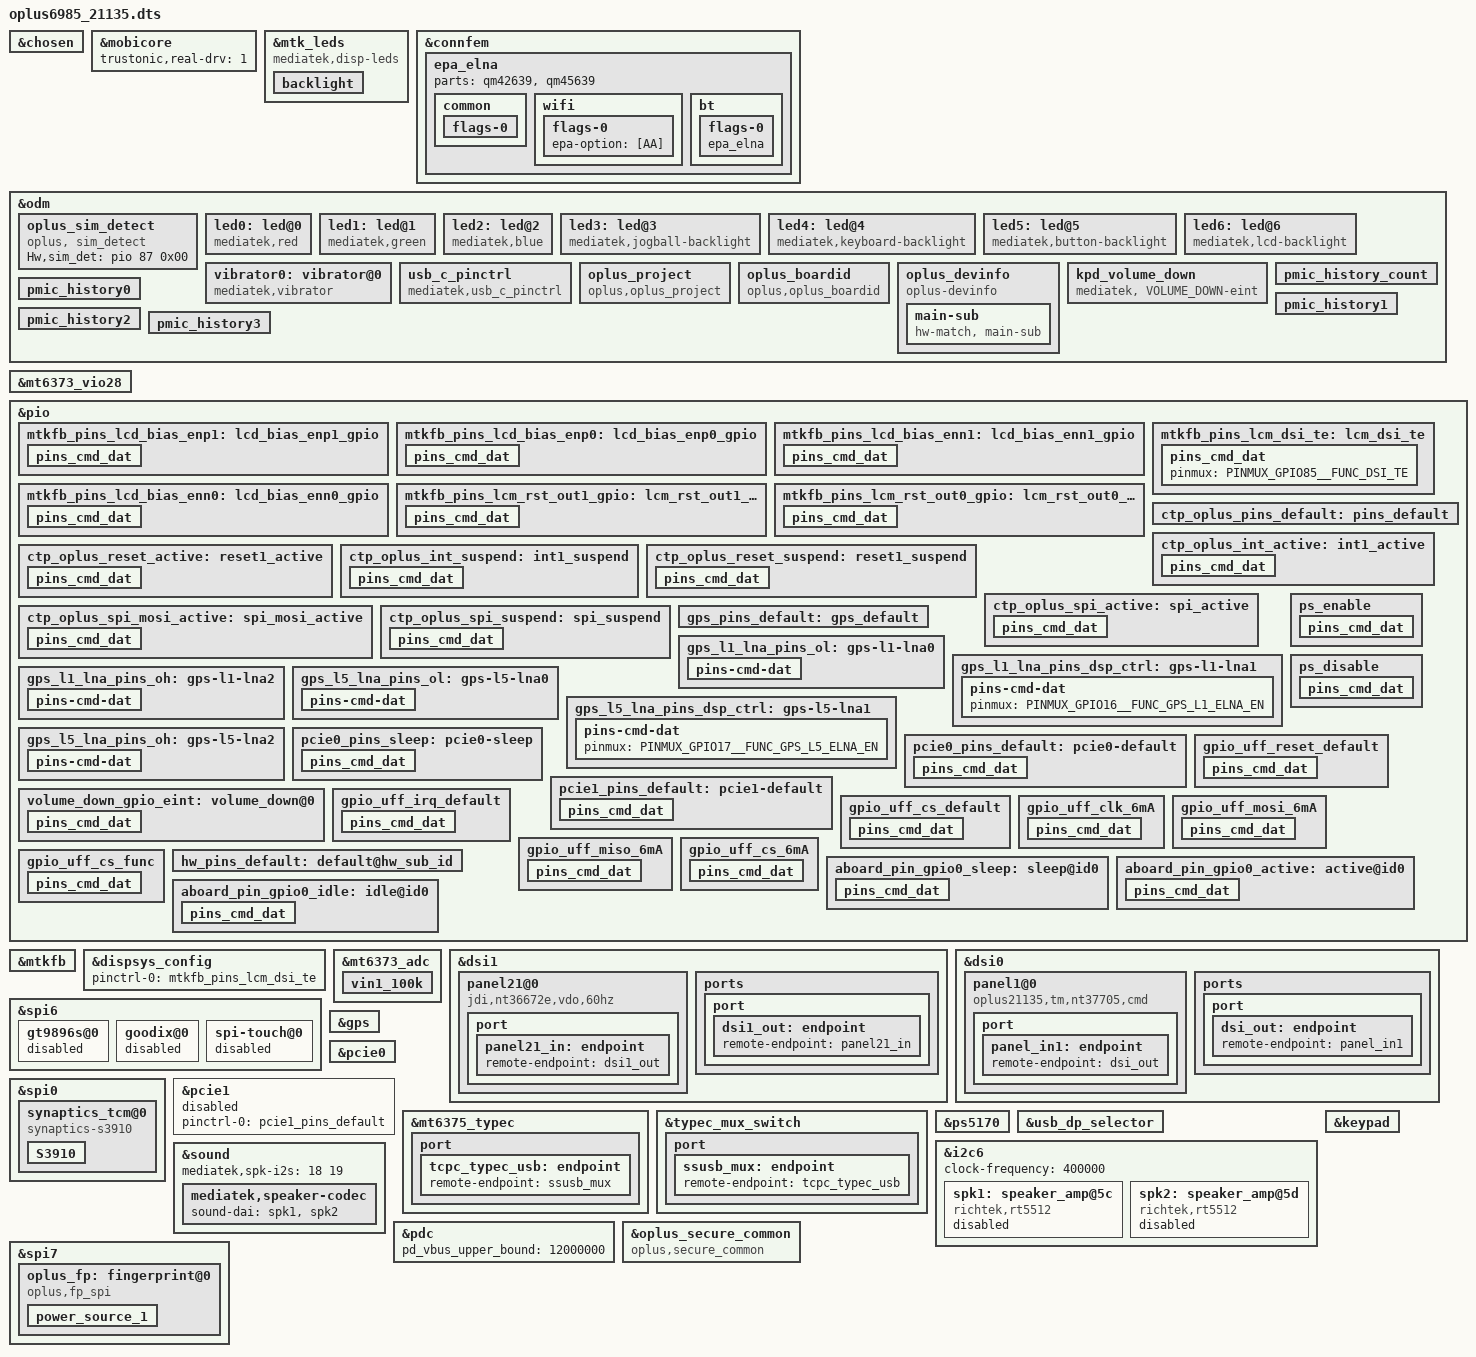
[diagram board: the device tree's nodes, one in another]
// SPDX-License-Identifier: (GPL-2.0 OR MIT)
/*
 * Copyright (C) 2022 MediaTek Inc.
 */
/dts-v1/;
/plugin/;
#include <dt-bindings/interrupt-controller/arm-gic.h>
#include <dt-bindings/interrupt-controller/irq.h>
#include <dt-bindings/pinctrl/mt6985-pinfunc.h>
#include <dt-bindings/phy/phy.h>

/* #ifdef OPLUS_FEATURE_CHG_BASIC */
/* Add for DX-2 charge device-tree */
#include "mediatek/oplus_charge_21135.dtsi"
/* #endif */

//#ifdef OPLUS_FEATURE_SENSOR
#include "mediatek/oplus_sensor_21135.dtsi"
//#endif

&chosen {
bootargs_ext = "console=tty0 root=/dev/ram vmalloc=400M \
loglevel=8 \
androidboot.hardware=mt6985 \
8250.nr_uarts=4 \
initcall_debug=1 \
mtk_printk_ctrl.disable_uart=0";
};

/* Trustonic Mobicore real driver */
&mobicore {
        trustonic,real-drv = <1>;
};

&mtk_leds {
	compatible = "mediatek,i2c-leds";

	backlight {
		led_mode = <6>;
		gate_enable = <1>;
		pwm_config = <0 1 0 0 0>;
	};
};

&connfem {
	/* Support Wifi & BT ePA/eLNA FEM on customer load */
	epa_elna {
		parts = <&qm42639 &qm45639>;

		common {
			flags-0 {
				rx-mode = [35];
				fe-ant-cnt = [82];
				fe-main-bt-share-lp2g = [80];
				fe-conn-spdt = [88];
				fe-reserved = [81];
			};
		};

		wifi {
			flags-0 {
				/* open-loop; */
				epa-option = [AA];
			};
		};

		bt {
			flags-0 {
				/* choose one of: epa_elna/epa/elna/bypass */
				epa_elna;
			};
		};
	};
};

&odm {
/* Add for sim detect */
    oplus_sim_detect {
        compatible = "oplus, sim_detect";
        Hw,sim_det = <&pio 87 0x00>;
    };
};

&mt6373_vio28 {
	regulator-compatible = "VIO28";
	regulator-name = "mt6373_vio28";
	status = "okay";
	regulator-min-microvolt = <3000000>;
	regulator-max-microvolt = <3000000>;
	regulator-always-on;
};

/** #ifdef OPLUS_DISPLAY_FEATURE **/
&odm {
	led0:led@0 {
		compatible = "mediatek,red";
		led_mode = <0>;
		data = <1>;
		pwm_config = <0 0 0 0 0>;
	};
	led1:led@1 {
		compatible = "mediatek,green";
		led_mode = <0>;
		data = <1>;
		pwm_config = <0 0 0 0 0>;
	};
	led2:led@2 {
		compatible = "mediatek,blue";
		led_mode = <0>;
		data = <1>;
		pwm_config = <0 0 0 0 0>;
	};
	led3:led@3 {
		compatible = "mediatek,jogball-backlight";
		led_mode = <0>;
		data = <1>;
		pwm_config = <0 0 0 0 0>;
	};
	led4:led@4 {
		compatible = "mediatek,keyboard-backlight";
		led_mode = <0>;
		data = <1>;
		pwm_config = <0 0 0 0 0>;
	};
	led5:led@5 {
		compatible = "mediatek,button-backlight";
		led_mode = <0>;
		data = <1>;
		pwm_config = <0 0 0 0 0>;
	};
	led6:led@6 {
		compatible = "mediatek,lcd-backlight";
		led_mode = <4>;
		data = <1>;
		pwm_config = <0 1 0 0 0>;
	};
	vibrator0:vibrator@0 {
		compatible = "mediatek,vibrator";
		vib_timer = <25>;
		vib_limit = <9>;
		vib_vol= <9>;
	};

	usb_c_pinctrl:usb_c_pinctrl {
		compatible = "mediatek,usb_c_pinctrl";
	};
};

&mtk_leds {
		compatible = "mediatek,disp-leds";
		backlight {
			label = "lcd-backlight";
			led_mode = <4>;
			min-brightness = <1>;
			max-brightness = <4095>;
			max-hw-brightness = <4095>;
			led-bits = <13>;
			trans-bits = <13>;
			default-state = "on";
	};
};
/** #endif OPLUS_DISPLAY_FEATURE **/

&pio {
	mtkfb_pins_lcd_bias_enp1: lcd_bias_enp1_gpio {
		pins_cmd_dat {
			pinmux = <PINMUX_GPIO84__FUNC_GPIO84>;
			slew-rate = <1>;
			output-high;
		};
	};

	mtkfb_pins_lcd_bias_enp0: lcd_bias_enp0_gpio {
		pins_cmd_dat {
			pinmux = <PINMUX_GPIO84__FUNC_GPIO84>;
			slew-rate = <1>;
			output-low;
		};
	};

	mtkfb_pins_lcd_bias_enn1: lcd_bias_enn1_gpio {
		pins_cmd_dat {
			pinmux = <PINMUX_GPIO84__FUNC_GPIO84>;
			slew-rate = <1>;
			output-high;
		};
	};

	mtkfb_pins_lcd_bias_enn0: lcd_bias_enn0_gpio {
		pins_cmd_dat {
			pinmux = <PINMUX_GPIO84__FUNC_GPIO84>;
			slew-rate = <1>;
			output-low;
		};
	};

	mtkfb_pins_lcm_rst_out1_gpio: lcm_rst_out1_gpio {
		pins_cmd_dat {
			pinmux = <PINMUX_GPIO86__FUNC_GPIO86>;
			slew-rate = <1>;
			output-high;
		};
	};

	mtkfb_pins_lcm_rst_out0_gpio: lcm_rst_out0_gpio {
		pins_cmd_dat {
			pinmux = <PINMUX_GPIO86__FUNC_GPIO86>;
			slew-rate = <1>;
			output-low;
		};
	};
	mtkfb_pins_lcm_dsi_te: lcm_dsi_te {
		pins_cmd_dat {
			pinmux = <PINMUX_GPIO85__FUNC_DSI_TE>;
		};
	};
};

&mtkfb {
	pinctrl-names = "lcd_bias_enp1_gpio", "lcd_bias_enp0_gpio",
		"lcd_bias_enn1_gpio", "lcd_bias_enn0_gpio",
		"lcm_rst_out1_gpio", "lcm_rst_out0_gpio",
		"mode_te_te";
	pinctrl-0 = <&mtkfb_pins_lcd_bias_enp1>;
	pinctrl-1 = <&mtkfb_pins_lcd_bias_enp0>;
	pinctrl-2 = <&mtkfb_pins_lcd_bias_enn1>;
	pinctrl-3 = <&mtkfb_pins_lcd_bias_enn0>;
	pinctrl-4 = <&mtkfb_pins_lcm_rst_out1_gpio>;
	pinctrl-5 = <&mtkfb_pins_lcm_rst_out0_gpio>;
	pinctrl-6 = <&mtkfb_pins_lcm_dsi_te>;

	status = "okay";
};

&dispsys_config {
	pinctrl-names = "mode_te_te";
	pinctrl-0 = <&mtkfb_pins_lcm_dsi_te>;
	status = "okay";
};

/* #ifdef OPLUS_FEATURE_DISPLAY */
&mt6373_adc {
	vin1_100k {
		channel = <AUXADC_VIN1>;
		pures = <ADC_PURES_100K>;
	};
};
/* #endif */ /* OPLUS_FEATURE_DISPLAY */

&dsi1 {
//	status = "okay";
	#address-cells = <1>;
	#size-cells = <0>;
	panel21@0 {
		compatible = "jdi,nt36672e,vdo,60hz";
		reg = <0>;
		pm-enable-gpios = <&pio 68 0>;
		reset-gpios = <&pio 75 0>;
		gate-ic = <4831>;
		pinctrl-names = "default";
		port {
			panel21_in: endpoint {
				remote-endpoint = <&dsi1_out>;
			};
		};
	};
	ports {
		port {
			dsi1_out: endpoint {
				remote-endpoint = <&panel21_in>;
			};
		};
	};
};

&dsi0 {
	status = "okay";
	#address-cells = <1>;
	#size-cells = <0>;
	/** #ifdef OPLUS_DISPLAY_FEATURE **/
	panel1@0 {
		compatible = "oplus21135,tm,nt37705,cmd";
		reg = <0>;
		pm-enable-gpios = <&pio 165 0>;
		reset-gpios = <&pio 86 0>;
		1p8-supply = <&mt6373_vrfio18_aif>;
		3p0-supply = <&mt6373_vmc>;
		pinctrl-names = "default";
		oplus-adfr-config = <33>;
		oplus-hpwm-bl-config = <0x643>;
		oplus-hpwm-mode = <0>;
		res-switch = <2>;
/* #ifdef OPLUS_FEATURE_DISPLAY_TEMP_COMPENSATION */
		io-channels = <&mt6373_adc AUXADC_VIN1>;
		io-channel-names = "panel-channel";
		oplus,temp-compensation-config = <5>;
		oplus,temp-compensation-dbv-group = <3516 1604 1511 1419 1328 1212 1096 950 761 544>;
		oplus,temp-compensation-temp-group = <(0-10) 0 10 20 25 30 35 40 45 51>;
		oplus,temp-compensation-data = [
			/* dbv > 3515 */
			10 14 18 10 14 10 14 18 3A 3A 3A 3A 3A 3A 3A 3A 3A 00 00 00 00 00 00 00 00	/* -20 ~ -10 */
			10 14 18 10 14 10 14 18 3A 3A 3A 3A 3A 3A 3A 3A 3A 00 00 00 00 00 00 00 00	/* -10 ~ 0 */
			14 18 1C 14 18 14 18 1C 39 39 39 39 39 39 39 39 39 00 00 00 00 00 00 00 00	/* 0 ~ 10 */
			18 1C 20 18 1C 18 1C 20 38 38 38 38 38 38 38 38 38 00 00 00 00 00 00 00 00	/* 10 ~ 20 */
			1C 20 24 1C 20 1C 20 24 37 37 37 37 37 37 37 37 37 00 00 00 00 00 00 00 00	/* 20 ~ 25 */
			24 28 30 24 28 24 28 30 37 37 37 37 37 37 37 37 37 00 00 00 00 00 00 00 00	/* 25 ~ 30 */
			28 2C 34 28 2C 28 2C 34 36 36 36 36 36 36 36 36 36 00 00 00 00 00 00 00 00	/* 30 ~ 35 */
			2C 30 38 2C 30 2C 30 38 36 36 36 36 36 36 36 36 36 00 00 00 00 00 00 00 00	/* 35 ~ 40 */
			30 34 3C 30 34 30 34 3C 35 35 35 35 35 35 35 35 35 00 00 00 00 00 00 00 00	/* 40 ~ 45 */
			34 38 40 34 38 34 38 40 35 35 35 35 35 35 35 35 35 00 00 00 00 00 00 00 00	/* 45 ~ 50 */
			38 3C 44 38 3C 38 3C 44 34 34 34 34 34 34 34 34 34 00 00 00 00 00 00 00 00	/* > 50 */

			/* 1604 <= dbv <= 3515 */
			10 14 18 10 14 10 14 18 1D 1D 26 1F 1F 28 1D 1D 26 00 00 00 00 00 00 00 00	/* -20 ~ -10 */
			10 14 18 10 14 10 14 18 1D 1D 26 1F 1F 28 1D 1D 26 00 00 00 00 00 00 00 00	/* -10 ~ 0 */
			14 18 1C 14 18 14 18 1C 1C 1C 25 1E 1E 27 1C 1C 25 00 00 00 00 00 00 00 00	/* 0 ~ 10 */
			18 1C 20 18 1C 18 1C 20 1C 1C 25 1E 1E 27 1C 1C 25 00 00 00 00 00 00 00 00	/* 10 ~ 20 */
			1C 20 24 18 1C 1C 20 24 1B 1B 24 1D 1D 26 1B 1B 24 00 00 00 00 00 00 00 00	/* 20 ~ 25 */
			24 28 30 24 28 24 28 30 1B 1B 24 1C 1C 25 1B 1B 24 00 00 00 00 00 00 00 00	/* 25 ~ 30 */
			28 2C 34 28 2C 28 2C 34 1A 1A 23 1B 1B 24 1A 1A 23 00 00 00 00 00 00 00 00	/* 30 ~ 35 */
			2C 30 38 2C 30 2C 30 38 1A 1A 23 1B 1B 24 1A 1A 23 00 00 00 00 00 00 00 00	/* 35 ~ 40 */
			30 34 3C 30 34 30 34 3C 19 19 22 1A 1A 23 19 19 22 00 00 00 00 00 00 00 00	/* 40 ~ 45 */
			34 38 40 34 38 34 38 40 19 19 22 1A 1A 23 19 19 22 00 00 00 00 00 00 00 00	/* 45 ~ 50 */
			38 3C 44 38 3C 38 3C 44 18 18 21 19 19 22 18 18 21 00 00 00 00 00 00 00 00	/* > 50 */

			/* 1511 <= dbv < 1604 */
			0C 10 14 0C 10 04 04 08 1D 1D 26 1F 1F 28 19 19 24 00 00 00 00 00 00 00 00	/* -20 ~ -10 */
			0C 10 14 0C 10 04 04 08 1D 1D 26 1F 1F 28 19 19 24 00 00 00 00 00 00 00 00	/* -10 ~ 0 */
			10 14 18 10 14 04 08 0C 1C 1C 25 1E 1E 27 19 19 24 00 00 00 00 00 00 00 00	/* 0 ~ 10 */
			14 18 1C 14 18 04 08 0C 1C 1C 25 1E 1E 27 19 19 24 00 00 00 00 00 00 00 00	/* 10 ~ 20 */
			18 1C 20 14 18 08 08 0C 1B 1B 24 1D 1D 26 19 19 24 00 00 00 00 00 00 00 00	/* 20 ~ 25 */
			20 24 2C 20 24 08 0C 10 1B 1B 24 1C 1C 25 19 19 24 00 00 00 00 00 00 00 00	/* 25 ~ 30 */
			24 28 30 24 28 08 10 14 1A 1A 23 1B 1B 24 18 18 24 00 00 00 00 00 00 00 00	/* 30 ~ 35 */
			28 2C 34 28 2C 08 10 14 1A 1A 23 1B 1B 24 18 18 24 00 00 00 00 00 00 00 00	/* 35 ~ 40 */
			2C 30 38 2C 30 08 14 18 19 19 22 1A 1A 23 18 18 24 00 00 00 00 00 00 00 00	/* 40 ~ 45 */
			30 34 3C 30 34 0C 14 18 19 19 22 1A 1A 23 18 18 24 00 00 00 00 00 00 00 00	/* 45 ~ 50 */
			34 38 40 34 38 0C 14 18 18 18 21 19 19 22 18 18 24 00 00 00 00 00 00 00 00	/* > 50 */

			/* 1419 <= dbv < 1511 */
			0C 0C 10 0C 10 04 04 08 1D 1D 26 1F 1F 28 19 19 24 00 00 00 00 00 00 00 00	/* -20 ~ -10 */
			0C 0C 10 0C 10 04 04 08 1D 1D 26 1F 1F 28 19 19 24 00 00 00 00 00 00 00 00	/* -10 ~ 0 */
			10 14 18 10 14 04 08 0C 1C 1C 25 1E 1E 27 19 19 24 00 00 00 00 00 00 00 00	/* 0 ~ 10 */
			14 18 1C 14 18 04 08 0C 1C 1C 25 1E 1E 27 19 19 24 00 00 00 00 00 00 00 00	/* 10 ~ 20 */
			18 1C 20 14 18 08 08 0C 1B 1B 24 1D 1D 26 19 19 24 00 00 00 00 00 00 00 00	/* 20 ~ 25 */
			1C 20 28 1C 20 08 0C 0C 1B 1B 24 1C 1C 25 19 19 24 00 00 00 00 00 00 00 00	/* 25 ~ 30 */
			20 24 2C 20 24 08 0C 10 1A 1A 23 1B 1B 24 18 18 24 00 00 00 00 00 00 00 00	/* 30 ~ 35 */
			24 28 30 24 28 08 0C 10 1A 1A 23 1B 1B 24 18 18 24 00 00 00 00 00 00 00 00	/* 35 ~ 40 */
			28 2C 34 28 2C 08 10 14 19 19 22 1A 1A 23 18 18 24 00 00 00 00 00 00 00 00	/* 40 ~ 45 */
			2C 30 38 2C 30 08 10 14 19 19 22 1A 1A 23 18 18 24 00 00 00 00 00 00 00 00	/* 45 ~ 50 */
			30 34 3C 30 34 08 10 14 18 18 21 19 19 22 18 18 24 00 00 00 00 00 00 00 00	/* > 50 */

			/* 1328 <= dbv < 1419 */
			0C 0C 10 08 0C 04 04 08 1D 1D 26 1F 1F 28 19 19 24 00 00 00 00 00 00 00 00	/* -20 ~ -10 */
			0C 0C 10 08 0C 04 04 08 1D 1D 26 1F 1F 28 19 19 24 00 00 00 00 00 00 00 00	/* -10 ~ 0 */
			10 14 18 0C 10 04 04 0C 1C 1C 25 1E 1E 27 19 19 24 00 00 00 00 00 00 00 00	/* 0 ~ 10 */
			10 14 18 10 14 04 08 0C 1C 1C 25 1E 1E 27 19 19 24 00 00 00 00 00 00 00 00	/* 10 ~ 20 */
			14 18 1C 10 14 04 08 0C 1B 1B 24 1D 1D 26 19 19 24 00 00 00 00 00 00 00 00	/* 20 ~ 25 */
			18 1C 24 18 1C 04 08 0C 1B 1B 24 1C 1C 25 19 19 24 00 00 00 00 00 00 00 00	/* 25 ~ 30 */
			1C 20 28 1C 20 08 08 0C 1A 1A 23 1B 1B 24 18 18 24 00 00 00 00 00 00 00 00	/* 30 ~ 35 */
			20 24 2C 20 24 08 0C 10 1A 1A 23 1B 1B 24 18 18 24 00 00 00 00 00 00 00 00	/* 35 ~ 40 */
			24 28 30 24 28 08 0C 10 19 19 22 1A 1A 23 18 18 24 00 00 00 00 00 00 00 00	/* 40 ~ 45 */
			28 2C 34 28 2C 08 10 14 19 19 22 1A 1A 23 18 18 24 00 00 00 00 00 00 00 00	/* 45 ~ 50 */
			2C 30 38 2C 30 08 10 14 18 18 21 19 19 22 18 18 24 00 00 00 00 00 00 00 00	/* > 50 */

			/* 1212 <= dbv < 1328 */
			08 0C 10 08 0C 04 04 08 1E 1E 27 1E 1E 27 19 19 24 00 00 00 00 00 00 00 00	/* -20 ~ -10 */
			0C 0C 10 08 0C 04 04 08 1D 1D 26 1E 1E 27 19 19 24 00 00 00 00 00 00 00 00	/* -10 ~ 0 */
			0C 0C 18 08 0C 04 04 0C 1D 1D 26 1E 1E 27 19 19 24 00 00 00 00 00 00 00 00	/* 0 ~ 10 */
			0C 10 18 0C 10 04 04 0C 1C 1C 25 1D 1D 26 19 19 24 00 00 00 00 00 00 00 00	/* 10 ~ 20 */
			10 14 18 0C 10 04 08 0C 1B 1B 24 1C 1C 25 19 19 24 00 00 00 00 00 00 00 00	/* 20 ~ 25 */
			14 18 20 14 18 04 08 0C 1B 1B 24 1C 1C 25 19 19 24 00 00 00 00 00 00 00 00	/* 25 ~ 30 */
			18 1C 24 18 1C 04 0C 14 1A 1A 23 1B 1B 24 18 18 24 00 00 00 00 00 00 00 00	/* 30 ~ 35 */
			1C 20 28 1C 20 04 0C 14 1A 1A 23 1B 1B 24 18 18 24 00 00 00 00 00 00 00 00	/* 35 ~ 40 */
			20 24 2C 20 24 08 08 10 19 19 22 1A 1A 23 18 18 24 00 00 00 00 00 00 00 00	/* 40 ~ 45 */
			24 28 30 24 28 08 08 10 19 19 22 1A 1A 23 18 18 24 00 00 00 00 00 00 00 00	/* 45 ~ 50 */
			28 2C 34 28 2C 08 08 10 18 18 21 19 19 22 18 18 24 00 00 00 00 00 00 00 00	/* > 50 */

			/* 1096 <= dbv < 1212 */
			08 10 18 10 18 04 04 08 1B 1B 26 1C 1C 27 18 18 26 00 8A 8A 8A 00 00 00 00	/* -20 ~ -10 */
			0C 14 18 10 18 04 04 08 1B 1B 26 1C 1C 27 18 18 26 00 00 00 00 00 00 00 00	/* -10 ~ 0 */
			0C 18 18 10 18 04 04 08 1B 1B 26 1C 1C 27 18 18 26 00 00 00 00 00 00 00 00	/* 0 ~ 10 */
			10 18 18 10 18 04 04 08 1B 1B 26 1C 1C 27 18 18 26 00 00 00 00 00 00 00 00	/* 10 ~ 20 */
			10 18 18 10 18 04 04 08 1B 1B 26 1C 1C 27 18 18 26 00 00 00 00 00 00 00 00	/* 20 ~ 25 */
			10 18 18 10 18 04 04 08 1B 1B 26 1C 1C 27 18 18 26 00 11 11 11 00 00 00 00	/* 25 ~ 30 */
			14 18 18 10 18 04 04 08 1B 1B 26 1C 1C 27 18 18 26 00 00 00 00 00 00 00 00	/* 30 ~ 35 */
			14 18 18 10 18 04 04 08 1B 1B 26 1C 1C 27 18 18 26 00 00 00 00 00 00 00 00	/* 35 ~ 40 */
			18 18 18 10 18 04 04 08 1B 1B 26 1C 1C 27 18 18 26 00 00 00 00 00 00 00 00	/* 40 ~ 45 */
			1C 18 18 10 18 04 04 08 1B 1B 26 1C 1C 27 18 18 26 00 00 00 00 00 00 00 00	/* 45 ~ 50 */
			1C 18 18 10 18 04 04 08 1A 1A 26 1C 1C 27 18 18 26 00 56 56 56 00 00 00 00	/* > 50 */

			/* 950 <= dbv < 1096 */
			08 10 10 0C 10 04 04 04 1B 1B 24 1B 1B 25 17 17 24 00 E1 E1 E1 00 00 00 00	/* -20 ~ -10 */
			08 10 10 0C 10 04 04 04 1B 1B 24 1B 1B 25 17 17 24 00 00 00 00 00 00 00 00	/* -10 ~ 0 */
			08 10 10 0C 10 04 04 04 1B 1B 24 1B 1B 25 17 17 24 00 00 00 00 00 00 00 00	/* 0 ~ 10 */
			0C 10 10 0C 10 04 04 04 1B 1B 24 1B 1B 25 17 17 24 00 00 00 00 00 00 00 00	/* 10 ~ 20 */
			0C 10 10 0C 10 04 04 04 1B 1B 24 1B 1B 25 17 17 24 00 00 00 00 00 00 00 00	/* 20 ~ 25 */
			0C 10 10 0C 10 04 04 04 1B 1B 24 1B 1B 25 17 17 24 00 11 11 11 00 00 00 00	/* 25 ~ 30 */
			10 10 10 0C 10 04 04 04 1B 1B 24 1B 1B 25 17 17 24 00 11 11 11 00 00 00 00	/* 30 ~ 35 */
			10 10 10 0C 10 04 04 04 1B 1B 24 1B 1B 25 17 17 24 00 00 00 00 00 00 00 00	/* 35 ~ 40 */
			14 10 10 0C 10 04 04 04 1B 1B 24 1B 1B 25 17 17 24 00 00 00 00 00 00 00 00	/* 40 ~ 45 */
			14 10 10 0C 10 04 04 04 1B 1B 24 1B 1B 25 17 17 24 00 00 00 00 00 00 00 00	/* 45 ~ 50 */
			14 10 10 0C 10 04 04 04 19 19 24 1B 1B 25 17 17 24 00 BE BE BE 00 00 00 00	/* > 50 */

			/* 761 <= dbv < 950 */
			04 10 10 08 10 04 04 04 1B 1B 24 1B 1B 25 16 16 24 00 E1 E1 E1 00 00 00 00	/* -20 ~ -10 */
			08 10 10 08 10 04 04 04 1B 1B 24 1B 1B 25 16 16 24 00 00 00 00 00 00 00 00	/* -10 ~ 0 */
			08 10 10 08 10 04 04 04 1B 1B 24 1B 1B 25 16 16 24 00 00 00 00 00 00 00 00	/* 0 ~ 10 */
			08 10 10 08 10 04 04 04 1B 1B 24 1B 1B 25 16 16 24 00 00 00 00 00 00 00 00	/* 10 ~ 20 */
			08 10 10 08 10 04 04 04 1B 1B 24 1B 1B 25 16 16 24 00 00 00 00 00 00 00 00	/* 20 ~ 25 */
			08 10 10 08 10 04 04 04 1B 1B 24 1B 1B 25 16 16 24 00 56 56 56 00 00 00 00	/* 25 ~ 30 */
			0C 10 10 08 10 04 04 04 1B 1B 24 1B 1B 25 16 16 24 00 22 22 22 00 00 00 00	/* 30 ~ 35 */
			0C 10 10 08 10 04 04 04 1B 1B 24 1B 1B 25 16 16 24 00 00 00 00 00 00 00 00	/* 35 ~ 40 */
			10 10 10 08 10 04 04 04 1B 1B 24 1B 1B 25 16 16 24 00 00 00 00 00 00 00 00	/* 40 ~ 45 */
			10 10 10 08 10 04 04 04 1B 1B 24 1B 1B 25 16 16 24 00 00 00 00 00 00 00 00	/* 45 ~ 50 */
			10 10 10 08 10 04 04 04 19 19 24 1B 1B 25 16 16 24 00 BE BE BE 00 00 00 00	/* > 50 */

			/* 544 <= dbv < 761 */
			04 08 0C 08 0C 00 00 00 1B 1B 24 1A 1A 25 15 15 24 00 F2 F2 F2 00 00 00 00	/* -20 ~ -10 */
			04 08 0C 08 0C 00 00 00 1B 1B 24 1A 1A 25 15 15 24 00 BE BE BE 00 00 00 00	/* -10 ~ 0 */
			04 08 0C 08 0C 00 00 00 1B 1B 23 1A 1A 25 15 15 24 00 68 68 68 00 00 00 00	/* 0 ~ 10 */
			04 08 0C 08 0C 00 00 00 1B 1B 24 1A 1A 25 15 15 24 00 34 34 34 00 00 00 00	/* 10 ~ 20 */
			08 08 0C 08 0C 00 00 00 1B 1B 24 1A 1A 25 15 15 24 00 34 34 34 00 00 00 00	/* 20 ~ 25 */
			08 08 0C 08 0C 00 00 00 1B 1B 24 1A 1A 25 15 15 24 00 68 68 68 00 00 00 00	/* 25 ~ 30 */
			08 08 0C 08 0C 00 00 00 1B 1B 24 1A 1A 25 15 15 24 00 11 11 11 00 00 00 00	/* 30 ~ 35 */
			08 08 0C 08 0C 00 00 00 1B 1B 24 1A 1A 25 15 15 24 00 11 11 11 00 00 00 00	/* 35 ~ 40 */
			08 08 0C 08 0C 00 00 00 1A 1A 24 1A 1A 25 15 15 24 00 34 34 34 00 00 00 00	/* 40 ~ 45 */
			08 08 0C 08 0C 00 00 00 1B 1B 24 1A 1A 25 15 15 24 00 00 00 00 00 00 00 00	/* 45 ~ 50 */
			08 08 0C 08 0C 00 00 00 18 18 24 1A 1A 25 15 15 24 00 BE BE BE 00 00 00 00	/* > 50 */

			/* dbv < 544 */
			00 08 0C 08 0C 00 00 00 1A 1A 23 1B 1B 25 14 14 24 15 38 38 38 00 00 00 00	/* -20 ~ -10 */
			04 08 0C 08 0C 00 00 00 1A 1A 23 1B 1B 25 14 14 24 15 15 15 15 00 00 00 00	/* -10 ~ 0 */
			04 08 0C 08 0C 00 00 00 1A 1A 23 1B 1B 25 14 14 24 00 D0 D0 D0 00 00 00 00	/* 0 ~ 10 */
			04 08 0C 08 0C 00 00 00 1A 1A 23 1B 1B 25 14 14 24 00 F2 F2 F2 00 00 00 00	/* 10 ~ 20 */
			04 08 0C 08 0C 00 00 00 1A 1A 23 1B 1B 25 14 14 24 00 AD AD AD 00 00 00 00	/* 20 ~ 25 */
			04 08 0C 08 0C 00 00 00 1A 1A 23 1B 1B 25 14 14 24 00 AD AD AD 00 00 00 00	/* 25 ~ 30 */
			04 08 0C 08 0C 00 00 00 19 19 22 1B 1B 25 14 14 24 00 BE BE BE 00 00 00 00	/* 30 ~ 35 */
			04 08 0C 08 0C 00 00 00 18 18 21 1B 1B 25 14 14 24 15 04 04 04 00 00 00 00	/* 35 ~ 40 */
			04 08 0C 08 0C 00 00 00 18 18 21 1B 1B 25 14 14 24 00 E1 E1 E1 00 00 00 00	/* 40 ~ 45 */
			04 08 0C 08 0C 00 00 00 18 18 21 1B 1B 25 14 14 24 00 E1 E1 E1 00 00 00 00	/* 45 ~ 50 */
			04 08 0C 08 0C 00 00 00 18 18 21 1B 1B 25 14 14 24 00 E1 E1 E1 00 00 00 00	/* > 50 */
		];
/* #endif */ /* OPLUS_FEATURE_DISPLAY_TEMP_COMPENSATION */
		port {
			panel_in1: endpoint {
				remote-endpoint = <&dsi_out>;
			};
		};
	};
	/** #endif OPLUS_DISPLAY_FEATURE **/
	ports {
		port {
			dsi_out: endpoint {
				remote-endpoint = <&panel_in1>;
			};
		};
	};
};

&spi6 {
	gt9896s@0 {
		status = "disabled";
	};
	goodix@0 {
		status = "disabled";
	};
	spi-touch@0 {
		status = "disabled";
	};
};

&spi0 {
	status = "okay";
	#address-cells = <1>;
	#size-cells = <0>;

	synaptics_tcm@0{
		compatible = "synaptics-s3910";
		reg = <0x0>;
		chip-name = "S3910";
		status = "okay";
		spi-max-frequency = <15000000>;
		/* Interrupt && Irq-gpio */
		interrupt-parent = <&pio>;
		interrupts = <8 0x2008>;

		/* Power Config */
		/* enable2v8_gpio  = <&pio 164 0x1>; */
		vdd_2v8-supply = <&mt6373_vtp>;
		vdd_2v8_volt = <3000000>;
		/* vcc_1v8-supply  = <&mt6373_vmc>; */
		/* vcc_1v8_volt = <1800000>; */

		/* Other HW Resource */

		irq-gpio = <&pio 8 0x2008>;
		reset-gpio = <&pio 67 0x1>;
		//cs-gpio = <&pio 110 0x00>;

		pinctrl-names = "default",  "oplus_int_active",
		"oplus_reset_active", "oplus_int_suspend",
		"oplus_reset_suspend", "oplus_spi_active",
		"oplus_spi_suspend";
		pinctrl-0 = <&ctp_oplus_pins_default>;
		pinctrl-1 = <&ctp_oplus_int_active>;
		pinctrl-2 = <&ctp_oplus_reset_active>;
		pinctrl-3 = <&ctp_oplus_int_suspend>;
		pinctrl-4 = <&ctp_oplus_reset_suspend>;
		pinctrl-5 = <&ctp_oplus_spi_active>, <&ctp_oplus_spi_mosi_active>;
		pinctrl-6 = <&ctp_oplus_spi_suspend>;

		touchpanel,max-num-support = <10>;
		touchpanel,tx-rx-num = <16 36>;
		touchpanel,panel-coords = <12400 27720>;
		touchpanel,display-coords = <1240 2772>;
		touchpanel,touchmajor-limit = <128 216>;
		touchpanel,elimination-range = <20 200 200>;
		touchpanel,int-mode = <1>; /*0: interrupt and disable, 1:interrupt and not disable*/
		touchpanel,smooth-level = <0 1 2 4 7 9>;
		touchpanel,smooth-level-charging = <0 2 4 7 8 9>;
		touchpanel,sensitive-level = <0 70 55 40 25 10>;
		touchpanel,single-optimized-time = <8>;
		touchpanel,high-frame-rate-time = <60>;

		vid_len = <2>;
		panel_type = <7 7>; /*type:7 TIANMA*/
		platform_support_project = <21135>;
		platform_support_project_dir = <21135>;
		platform_support_project_commandline = "oplus21135_tm_nt37705_fhd_dsi_cmd_lcm_drv", "oplus21121_boe_nt37701a_fhd_dsi_cmd_lcm_drv";

		prevention,curved_screen_V2;
		prevention,grip_disable_level = <6>;
		prevention,updelay_time_ms = <30>;
		prevention,makeup_cnt_weight = <4 1 2 2 2>;
		prevention,large_corner_range = <1380 3400>;
		prevention,large_corner_judge_condition = <500 300 1000 7 7>;
		prevention,trx_reject_condition = <8 7 7>;
		prevention,trx_strict_reject_condition = <8 6 6>;
		prevention,large_judge_time_ms = <500 50 30>;
		prevention,large_exit_condition = <8 8 2>;
		prevention,single_channel_width = <320 320>;
		prevention,normal_tap_condition = <10 350>;
		prevention,long_edge_condition = <179 90 120 80>;
		prevention,long_strict_edge_condition = <160 60>;
		prevention,long_fingerhold_condition = <70 6 4 4>;
		prevention,short_edge_condition = <179 90 120 80>;
		prevention,short_strict_edge_condition = <160 60>;
		prevention,large_strict_exit_condition = <6 6>;
		prevention,top_corner_config = <250 750 1000>;
		prevention,edge_swipe_config = <340 1130>;

		prevention,curved_screen_V4;
		prevention,long_eliminate_point_type = <2 12400 9240 240 27720 300 1>;
		prevention,long_fingerhold_condition2 = <700 2000 0 0>;
		prevention,top_corner_config2 =<3 80 600 1500 0>;
		prevention,hor_long_top_corner_config =<300 2000 0 0>;
		prevention,top_middle_config =<12400 1000 1000 0>;
		prevention,corner_eliminate_point_type =<0 1380 2270 1>;
		prevention,finger_hold_differ_size = <1 0 400 300>;
		prevention,finger_hold_max_rx_exit_distance = <5 350 2300>;
		prevention,max_rx_exit_distance = <1 5 150 350 2000>;
		prevention,dynamic_finger_hold_exit_distance = <1 350 2300 450>;
		prevention,edge_sliding_matched_support = <1 150 3 0>;

		/* SW Support Feature Control */
		black_gesture_support;
		sportify_aod_gesture_support;
		pressure_report_support;
		charger_pump_support;
		game_switch_support;
		glove_mode_support;
		smart_gesture_support;
		spi_port_support;
		fw_update_app_support;
		fingerprint_underscreen_support;
		freq_hop_simulate_support;
		report_flow_unlock_support;
		screenoff_fingerprint_info_support;
		irq_need_dev_resume_ok;
		enable_point_auto_change;
		kernel_grip_support;
		//grip_no_driver_support;
		health_monitor_support;
		black_gesture_indep_support;
		snr_read_support;
		exception_upload_support;
		/*
		 *Virtual Key Config:
		 *1:touchpanel,button-type: <virtualkey_type  supportted_button-map>
		 *virtualkey_type:
		 *Type 1: using board_properties
		 *Type 2: using same IC (button zone&& touch zone are seprate)
		 *Type 3: using diffrent IC (button zone&& touch zone are seprate)
		 *Type 4: No need of virtual key process
		 *supportted_button-map:select|menu|home|back
		 *
		 *2:touchpanel,button-map
		 *type (X1,Y1)(X2,Y2)(X3,Y3)(Width_X,Hight_Y)--Only when button-type is 0
		 */
		touchpanel,button-type = <4>;
		touchpanel.button-TRx = <0 0>;

		S3910 {
			switch_report_rate;
			report_rate_default = <60>;
			report_rate_game_value = <0x03>;
			fps_report_rate = <60 2 90 3 120 3>;//1:360Hz 2:125Hz 3:240Hz
			fwupdate_bootloader = <1>;
			normal_config_version = <2>;
			default_gesture_mask = <8191>;
		};
	};

};

&pio {
	ctp_oplus_pins_default: pins_default {
	};
	ctp_oplus_int_active: int1_active {
		pins_cmd_dat {
			pinmux = <PINMUX_GPIO8__FUNC_GPIO8>;
			bias-disable;
			input-enable;
		};
	};
	ctp_oplus_reset_active: reset1_active {
		pins_cmd_dat {
			pinmux = <PINMUX_GPIO67__FUNC_GPIO67>;
			output-high;
		};
	};
	ctp_oplus_int_suspend: int1_suspend {
		pins_cmd_dat {
			pinmux = <PINMUX_GPIO8__FUNC_GPIO8>;
			output-low;
		};
	};
	ctp_oplus_reset_suspend: reset1_suspend {
		pins_cmd_dat {
			pinmux = <PINMUX_GPIO67__FUNC_GPIO67>;
			output-low;
		};
	};
	ctp_oplus_spi_active: spi_active {
		pins_cmd_dat {
			pinmux = <PINMUX_GPIO151__FUNC_SPI0_CSB>,
				<PINMUX_GPIO152__FUNC_SPI0_MO>,
				<PINMUX_GPIO153__FUNC_SPI0_CLK>;
			bias-disable;
			drive-strength = <4>;
		};
	};
	ctp_oplus_spi_mosi_active: spi_mosi_active {
		pins_cmd_dat {
			pinmux = <PINMUX_GPIO150__FUNC_SPI0_MI>;
			bias-pull-up;
			drive-strength = <4>;
		};
	};
	ctp_oplus_spi_suspend: spi_suspend {
		pins_cmd_dat {
			pinmux = < PINMUX_GPIO150__FUNC_GPIO150>,
				< PINMUX_GPIO151__FUNC_GPIO151>,
				<PINMUX_GPIO152__FUNC_GPIO152>,
				< PINMUX_GPIO153__FUNC_GPIO153>;
			bias-disable;
			output-low;
			drive-strength = <4>;
		};
	};
};
/* GPS GPIO standardization start */
&pio {
	gps_pins_default: gps_default {
	};
	gps_l1_lna_pins_ol: gps-l1-lna0 {
		pins-cmd-dat {
			pinmux = <PINMUX_GPIO16__FUNC_GPIO16>;
			output-low;
		};
	};
	gps_l1_lna_pins_dsp_ctrl: gps-l1-lna1 {
		pins-cmd-dat {
			pinmux = <PINMUX_GPIO16__FUNC_GPS_L1_ELNA_EN>;
		};
	};
	gps_l1_lna_pins_oh: gps-l1-lna2 {
		pins-cmd-dat {
			pinmux = <PINMUX_GPIO16__FUNC_GPIO16>;
			output-high;
		};
	};
	gps_l5_lna_pins_ol: gps-l5-lna0 {
		pins-cmd-dat {
			pinmux = <PINMUX_GPIO17__FUNC_GPIO17>;
			output-low;
		};
	};
	gps_l5_lna_pins_dsp_ctrl: gps-l5-lna1 {
		pins-cmd-dat {
			pinmux = <PINMUX_GPIO17__FUNC_GPS_L5_ELNA_EN>;
		};
	};
	gps_l5_lna_pins_oh: gps-l5-lna2 {
		pins-cmd-dat {
			pinmux = <PINMUX_GPIO17__FUNC_GPIO17>;
			output-high;
		};
	};
};
&gps {
	pinctrl-names = "default",
		"gps_l1_lna_disable",
		"gps_l1_lna_dsp_ctrl",
		"gps_l1_lna_enable",
		"gps_l5_lna_disable",
		"gps_l5_lna_dsp_ctrl",
		"gps_l5_lna_enable";
	pinctrl-0 = <&gps_pins_default>;
	pinctrl-1 = <&gps_l1_lna_pins_ol>;
	pinctrl-2 = <&gps_l1_lna_pins_dsp_ctrl>;
	pinctrl-3 = <&gps_l1_lna_pins_oh>;
	pinctrl-4 = <&gps_l5_lna_pins_ol>;
	pinctrl-5 = <&gps_l5_lna_pins_dsp_ctrl>;
	pinctrl-6 = <&gps_l5_lna_pins_oh>;
	status = "okay";
};
/* GPS GPIO standardization end */

/* PCIe pinmux start */
&pcie0 {
	pinctrl-names = "default", "sleep";
	pinctrl-0 = <&pcie0_pins_default>;
	pinctrl-1 = <&pcie0_pins_sleep>;
	status = "okay";
};

&pcie1 {
	pinctrl-names = "default";
	pinctrl-0 = <&pcie1_pins_default>;
	status = "disabled";
};

&pio {
	pcie0_pins_default: pcie0-default {
		pins_cmd_dat {
			/* PINMUX_GPIO231__FUNC_PCIE_WAKEN for Falcon */
			pinmux = <PINMUX_GPIO230__FUNC_PCIE_PERSTN>,
				 <PINMUX_GPIO232__FUNC_PCIE_CLKREQN>;
			bias-pull-up;
		};
	};

	pcie0_pins_sleep: pcie0-sleep {
		pins_cmd_dat {
			/* PINMUX_GPIO231__FUNC_GPIO231 for Falcon */
			pinmux = <PINMUX_GPIO230__FUNC_GPIO230>,
				 <PINMUX_GPIO232__FUNC_GPIO232>;
			bias-pull-down;
			input-enable;
		};
	};

	pcie1_pins_default: pcie1-default {
		pins_cmd_dat {
			pinmux = <PINMUX_GPIO0__FUNC_PCIE_PERSTN_P1>,
				 <PINMUX_GPIO1__FUNC_PCIE_WAKEN_P1>,
				 <PINMUX_GPIO2__FUNC_PCIE_CLKREQN_P1>;
			bias-pull-up;
		};
	};
};
/* PCIe pinmux end */

/* usb typec mux start */
&pio {

	ps_enable: ps_enable {
		pins_cmd_dat {
			//pinmux = <PINMUX_GPIO204__FUNC_GPIO204>;
			//output-high;
		};
	};

	ps_disable: ps_disable {
		pins_cmd_dat {
			//pinmux = <PINMUX_GPIO204__FUNC_GPIO204>;
			//output-low;
		};
	};

};

/*&gpio_keys {
        volumedown {
            label = "Volume_Down";
            linux,code = <114>;
            gpios = <&pio 11 1>;
            wakeup-source;
            debounce-interval = <5>;
        };
};*/
&mt6375_typec {
	port {
		tcpc_typec_usb: endpoint {
			remote-endpoint = <&ssusb_mux>;
		};
	};
};

&typec_mux_switch {
	orientation-switch;
	mode-switch;
	accessory;
	port {
		ssusb_mux: endpoint {
			remote-endpoint = <&tcpc_typec_usb>;
		};
	};
};

&ps5170 {
	pinctrl-names = "enable", "disable";
	pinctrl-0 = <&ps_enable>;
	pinctrl-1 = <&ps_disable>;
	status = "okay";
};

&usb_dp_selector {
	status = "okay";
};
/* usb typec mux end */

#include "mediatek/cust_mt6985_touch_1080x2400.dtsi"
#include "mediatek/oplus_nfc_21135.dtsi"

&i2c6 {
        clock-frequency = <400000>;

	spk1: speaker_amp@5c {
		compatible = "richtek,rt5512";
		#sound-dai-cells = <0>;
		reg = <0x5c>;
		status = "disable";
		sound-name-prefix = "Left";
	};

	spk2: speaker_amp@5d {
		compatible = "richtek,rt5512";
		#sound-dai-cells = <0>;
		reg = <0x5d>;
		status = "disable";
		sound-name-prefix = "Right";
	};
};


&sound {
	mediatek,spk-i2s = <18 19>;
	mediatek,speaker-codec {
		sound-dai = <&spk1>, <&spk2>;
	};
};

&pdc {
	pd_vbus_upper_bound = <12000000>;
};

&odm {
/*OPLUS_FEATURE_OEM_OCDT oppo project start */
	oplus_project:oplus_project {
		compatible = "oplus,oplus_project";
	};

	oplus_boardid:oplus_boardid {
		compatible = "oplus,oplus_boardid";
		oplus_boardid,dtsino="21135";//only one u32
		oplus_boardid,pcbmask="0xffff";//all mask 0xffff
	};

	oplus_devinfo:oplus_devinfo {
		compatible = "oplus-devinfo";
		pinctrl-names = "default", "aboard_gpio0_sleep", "aboard_gpio0_active", "aboard_gpio0_idle";
		pinctrl-0 = <&hw_pins_default>;
		pinctrl-1 = <&aboard_pin_gpio0_sleep>;
		pinctrl-2 = <&aboard_pin_gpio0_active>;
		pinctrl-3 = <&aboard_pin_gpio0_idle>;
		main-sub {
			use_tristate_gpio;
			compatible = "hw-match, main-sub";
			aboard-gpio0 = <&pio 206 0x00>;
			aboard-patterns = <0>;        /*0[high-resistance] 1[pull-down] 2[pull-up]*/
			/*main board*/
			match-projects = <21135>;
		};
	};

	kpd_volume_down:kpd_volume_down {
		compatible = "mediatek, VOLUME_DOWN-eint";
		interrupt-parent = <&pio>;
		interrupts = <11 IRQ_TYPE_EDGE_FALLING 11 0>;
		debounce = <32000>;
		status = "okay";
	};

	pmic_history_count:pmic_history_count {
	};
	pmic_history0:pmic_history0 {
	};
	pmic_history1:pmic_history1 {
	};
	pmic_history2:pmic_history2 {
	};
	pmic_history3:pmic_history3 {
	};

};
/*endif*/


&keypad {
        keypad,volume-down = <&pio 11 0x00>;
        pinctrl-names = "volume_down_as_int";
        pinctrl-0 = <&volume_down_gpio_eint>;
        status = "okay";
};

&pio {
        volume_down_gpio_eint:volume_down@0{
                pins_cmd_dat {
                        pinmux = <PINMUX_GPIO11__FUNC_GPIO11>;
                        slew-rate = <0>;  /*direction 0:in, 1:out*/
                        input-enable;
                        bias-disable;
                };
        };
};

//#ifdef OPLUS_FEATURE_SECURITY_COMMON
&oplus_secure_common {
	compatible = "oplus,secure_common";
	oplus,sec_reg_num = <0>;
	oplus,sec_en_anti_reg = <0>;
	oplus,sec_override1_reg = <0>;
	oplus,override1_en_value = <0>;
};
//#endif

/* FINGERPRINT start */
&spi7 {
#address-cells = <1>;
#size-cells = <0>;
status = "okay";
oplus_fp: fingerprint@0 {
		compatible = "oplus,fp_spi";
		reg = <0>;
		spi-max-frequency = <8000000>;
		spi-id = <1>;
		spi-irq = <9>;
		spi-reg = <11010000>;

		uff,gpio_irq = <&pio 9 0x00>;
		uff,gpio_reset = <&pio 209 0x00>;
		uff,gpio_cs = <&pio 169 0x00>;
		pinctrl-names = "default", "fp_spi_driver", "fp_cs_func";
		pinctrl-0 = <&gpio_uff_irq_default>, <&gpio_uff_reset_default>, <&gpio_uff_cs_default>;
		pinctrl-1 = <&gpio_uff_clk_6mA>, <&gpio_uff_mosi_6mA>, <&gpio_uff_miso_6mA>, <&gpio_uff_cs_6mA>;
		pinctrl-2 = <&gpio_uff_cs_func>;

		dvdd-supply = <&mt6373_vfp>;
		dvdd-config = <3000000 3000000 150000>;
		power-num = <1>;
		status = "okay";
		power_source_1 {
			power-mode = <1>;
			power-name = "dvdd";
			power-config = "dvdd-config";
			delay-time = <0>;
		};
	};
};

&pio{
gpio_uff_reset_default: gpio_uff_reset_default {
				pins_cmd_dat {
					pinmux = <PINMUX_GPIO209__FUNC_GPIO209>;
					slew-rate = <1>;
					output-low;
				};
			};
gpio_uff_irq_default: gpio_uff_irq_default {
				pins_cmd_dat {
					pinmux = <PINMUX_GPIO9__FUNC_GPIO9>;
					slew-rate = <1>;
					bias-disable;
					output-low;
				};
			};

gpio_uff_cs_default: gpio_uff_cs_default {
				pins_cmd_dat {
					pinmux = <PINMUX_GPIO169__FUNC_GPIO169>;
					slew-rate = <1>;
					bias-disable;
					output-low;
				};
			};


gpio_uff_clk_6mA: gpio_uff_clk_6mA {
				pins_cmd_dat {
					pinmux = <PINMUX_GPIO171__FUNC_SPI7_B_CLK>;
					drive-strength = <2>;
				};
			};
gpio_uff_mosi_6mA: gpio_uff_mosi_6mA {
				pins_cmd_dat {
					pinmux = <PINMUX_GPIO170__FUNC_SPI7_B_MO>;
					drive-strength = <2>;
				};
			};
gpio_uff_miso_6mA: gpio_uff_miso_6mA {
				pins_cmd_dat {
					pinmux = <PINMUX_GPIO168__FUNC_SPI7_B_MI>;
					drive-strength = <2>;
				};
			};

gpio_uff_cs_6mA: gpio_uff_cs_6mA {
				pins_cmd_dat {
					pinmux = <PINMUX_GPIO169__FUNC_SPI7_B_CSB>;
					drive-strength = <2>;
				};
			};

gpio_uff_cs_func: gpio_uff_cs_func {
					pins_cmd_dat {
					pinmux = <PINMUX_GPIO169__FUNC_SPI7_B_CSB>;
					drive-strength = <2>;
				};
			};

	hw_pins_default:default@hw_sub_id {
	};

	aboard_pin_gpio0_sleep:sleep@id0 {
		pins_cmd_dat {
			pinmux = <PINMUX_GPIO206__FUNC_GPIO206>;
			slew-rate = <0>;
			bias-pull-down;
			input-enable;
		};
	};

	aboard_pin_gpio0_active:active@id0 {
		pins_cmd_dat {
			pinmux = <PINMUX_GPIO206__FUNC_GPIO206>;
			slew-rate = <0>;
			bias-pull-up;
			input-enable;
		};
	};

	aboard_pin_gpio0_idle:idle@id0 {
		pins_cmd_dat {
			pinmux = <PINMUX_GPIO206__FUNC_GPIO206>;
			slew-rate = <0>;
			bias-disable;
			input-enable;
		};
	};
};
/* FINGERPRINT end */

#include "mediatek/cust_mt6985_luna_audio.dtsi"
#include "mediatek/cust_k6985_connfem.dtsi"
#include "mediatek/cust_mt6985_luna_camera_v4l2.dtsi"
#include <oplus6985_21135/cust.dtsi>
#include "mediatek/cust_mt6985_luna_thermal.dtsi"
/*End of this file, DO NOT ADD ANYTHING HERE*/

